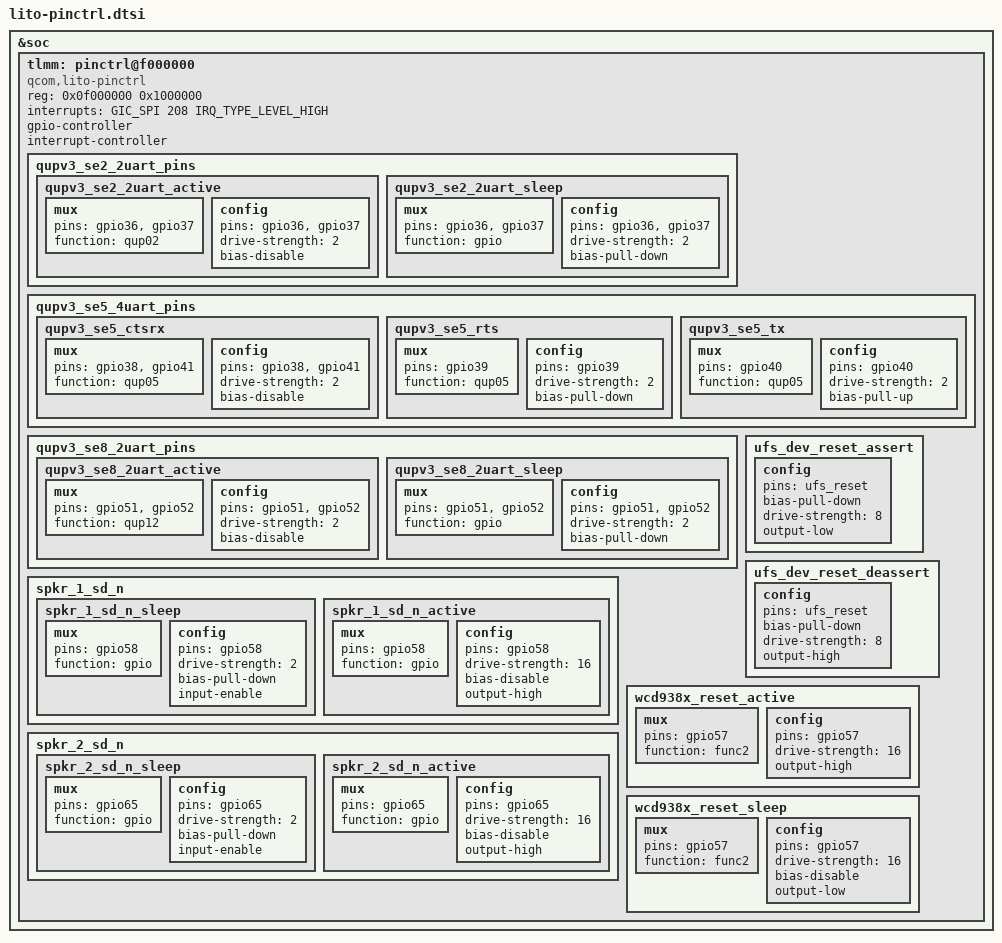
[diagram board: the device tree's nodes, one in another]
// SPDX-License-Identifier: GPL-2.0-only
/*
 * Copyright (c) 2018-2019, The Linux Foundation. All rights reserved.
 */

&soc {
	tlmm: pinctrl@f000000 {
		compatible = "qcom,lito-pinctrl";
		reg = <0x0f000000 0x1000000>;
		interrupts = <GIC_SPI 208 IRQ_TYPE_LEVEL_HIGH>;
		gpio-controller;
		#gpio-cells = <2>;
		interrupt-controller;
		#interrupt-cells = <2>;

		qupv3_se2_2uart_pins: qupv3_se2_2uart_pins {
			qupv3_se2_2uart_active: qupv3_se2_2uart_active {
				mux {
					pins = "gpio36", "gpio37";
					function = "qup02";
				};

				config {
					pins = "gpio36", "gpio37";
					drive-strength = <2>;
					bias-disable;
				};
			};

			qupv3_se2_2uart_sleep: qupv3_se2_2uart_sleep {
				mux {
					pins = "gpio36", "gpio37";
					function = "gpio";
				};

				config {
					pins = "gpio36", "gpio37";
					drive-strength = <2>;
					bias-pull-down;
				};
			};
		};

		qupv3_se5_4uart_pins: qupv3_se5_4uart_pins {
			qupv3_se5_ctsrx: qupv3_se5_ctsrx {
				mux {
					pins = "gpio38", "gpio41";
					function = "qup05";
				};

				config {
					pins = "gpio38", "gpio41";
					drive-strength = <2>;
					bias-disable;
				};
			};

			qupv3_se5_rts: qupv3_se5_rts {
				mux {
					pins = "gpio39";
					function = "qup05";
				};

				config {
					pins = "gpio39";
					drive-strength = <2>;
					bias-pull-down;
				};
			};

			qupv3_se5_tx: qupv3_se5_tx {
				mux {
					pins = "gpio40";
					function = "qup05";
				};

				config {
					pins = "gpio40";
					drive-strength = <2>;
					bias-pull-up;
				};
			};
		};

		qupv3_se8_2uart_pins: qupv3_se8_2uart_pins {
			qupv3_se8_2uart_active: qupv3_se8_2uart_active {
				mux {
					pins = "gpio51", "gpio52";
					function = "qup12";
				};

				config {
					pins = "gpio51", "gpio52";
					drive-strength = <2>;
					bias-disable;
				};
			};

			qupv3_se8_2uart_sleep: qupv3_se8_2uart_sleep {
				mux {
					pins = "gpio51", "gpio52";
					function = "gpio";
				};

				config {
					pins = "gpio51", "gpio52";
					drive-strength = <2>;
					bias-pull-down;
				};
			};
		};

		ufs_dev_reset_assert: ufs_dev_reset_assert {
			config {
				pins = "ufs_reset";
				bias-pull-down;		/* default: pull down */
				/*
				 * UFS_RESET driver strengths are having
				 * different values/steps compared to typical
				 * GPIO drive strengths.
				 *
				 * Following table clarifies:
				 *
				 * HDRV value | UFS_RESET | Typical GPIO
				 *   (dec)    |   (mA)    |    (mA)
				 *     0      |   0.8     |    2
				 *     1      |   1.55    |    4
				 *     2      |   2.35    |    6
				 *     3      |   3.1     |    8
				 *     4      |   3.9     |    10
				 *     5      |   4.65    |    12
				 *     6      |   5.4     |    14
				 *     7      |   6.15    |    16
				 *
				 * POR value for UFS_RESET HDRV is 3 which means
				 * 3.1mA and we want to use that. Hence just
				 * specify 8mA to "drive-strength" binding and
				 * that should result into writing 3 to HDRV
				 * field.
				 */
				drive-strength = <8>;	/* default: 3.1 mA */
				output-low; /* active low reset */
			};
		};

		ufs_dev_reset_deassert: ufs_dev_reset_deassert {
			config {
				pins = "ufs_reset";
				bias-pull-down;		/* default: pull down */
				/*
				 * default: 3.1 mA
				 * check comments under ufs_dev_reset_assert
				 */
				drive-strength = <8>;
				output-high; /* active low reset */
			};
		};

		/* WSA speaker reset pins */
		spkr_1_sd_n {
			spkr_1_sd_n_sleep: spkr_1_sd_n_sleep {
				mux {
					pins = "gpio58";
					function = "gpio";
				};

				config {
					pins = "gpio58";
					drive-strength = <2>;   /* 2 mA */
					bias-pull-down;
					input-enable;
				};
			};

			spkr_1_sd_n_active: spkr_1_sd_n_active {
				mux {
					pins = "gpio58";
					function = "gpio";
				};

				config {
					pins = "gpio58";
					drive-strength = <16>;   /* 16 mA */
					bias-disable;
					output-high;
				};
			};
		};

		spkr_2_sd_n {
			spkr_2_sd_n_sleep: spkr_2_sd_n_sleep {
				mux {
					pins = "gpio65";
					function = "gpio";
				};

				config {
					pins = "gpio65";
					drive-strength = <2>;   /* 2 mA */
					bias-pull-down;
					input-enable;
				};
			};

			spkr_2_sd_n_active: spkr_2_sd_n_active {
				mux {
					pins = "gpio65";
					function = "gpio";
				};

				config {
					pins = "gpio65";
					drive-strength = <16>;   /* 16 mA */
					bias-disable;
					output-high;
				};
			};
		};

		wcd938x_reset_active: wcd938x_reset_active {
			mux {
				pins = "gpio57";
				function = "func2";
			};

			config {
				pins = "gpio57";
				drive-strength = <16>;
				output-high;
			};
		};

		wcd938x_reset_sleep: wcd938x_reset_sleep {
			mux {
				pins = "gpio57";
				function = "func2";
			};

			config {
				pins = "gpio57";
				drive-strength = <16>;
				bias-disable;
				output-low;
			};
		};
	};
};
